# EMU_PRM register map
Vendor: Texas Instruments
Peripheral module from a debugger description file (folder am571x).
Registers are 32-bit, access per field, reset 0x30000 unless marked. A register's access mark holds for its fields unless they carry their own. Offsets are as the file gives them; lines under a group give offsets from that group; [hi:lo] are bit positions; {n}, {i} and the like mark numbered series; 'fields as' and 'values as' point back to an identical list; <NAME> marks a mode.

## EMU_PRM
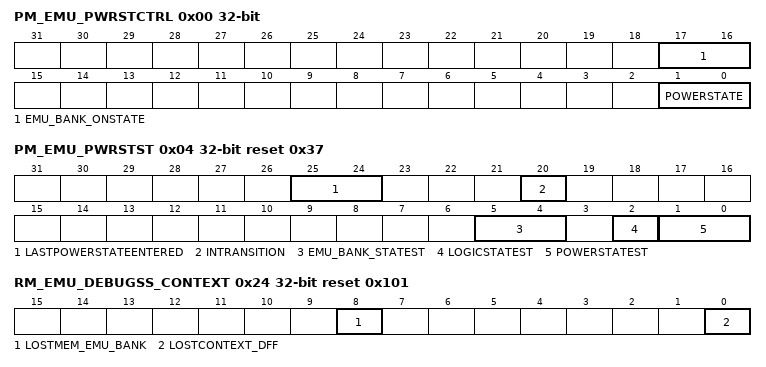
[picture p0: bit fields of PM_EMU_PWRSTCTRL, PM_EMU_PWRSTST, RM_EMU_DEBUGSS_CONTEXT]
0x00 PM_EMU_PWRSTCTRL ro — This register controls the EMU power state to reach upon a domain sleep transition
  [17:16] EMU_BANK_ONSTATE — EMU memory state when domain is ON.
    3=MEM_ON (Memory bank is on when the domain is ON.)
  [1:0] POWERSTATE — Power state control
    0=OFF (OFF state)
0x04 PM_EMU_PWRSTST reset 0x37 — This register provides a status on the EMU domain current power state. [warm reset insensitive]
  [25:24] LASTPOWERSTATEENTERED rw — Last low power state entered. Set to 0x3 upon write of the same only. This register is intended for debug purpose only.
    0=OFF (Power domain was previously OFF); 1=RET (Power domain was previously in RETENTION); 2=INACTIVE (Power domain was previously ON-INACTIVE); 3=ON (Power domain was previously ON-ACTIVE)
  [20] INTRANSITION ro — Domain transition status
    0=NO (No on-going transition on power domain); 1=ONGOING (Power domain transition is in progress.)
  [5:4] EMU_BANK_STATEST ro — EMU memory bank state status
    0=MEM_OFF (Memory is OFF); 3=MEM_ON (Memory is ON It is supplied by WKUP LDO)
  [2] LOGICSTATEST ro — Logic state status
    0=OFF (Logic in domain is OFF); 1=ON (Logic in domain is ON)
  [1:0] POWERSTATEST ro — Current power state status
    0=OFF (Power domain is OFF); 3=ON (Power domain is ON-ACTIVE)
0x24 RM_EMU_DEBUGSS_CONTEXT reset 0x101 — This register contains dedicated DEBUGSS context statuses. [warm reset insensitive]
  [8] LOSTMEM_EMU_BANK rw — Specify if memory-based context in EMU_BANK memory bank has been lost due to a previous power transition or other reset source.
    0=MAINTAINED (Context has been maintained); 1=LOST (Context has been lost)
  [0] LOSTCONTEXT_DFF rw — Specify if DFF-based context has been lost due to a previous power transition or other reset source. (set upon assertion of EMU_RST signal)
    values as LOSTMEM_EMU_BANK
